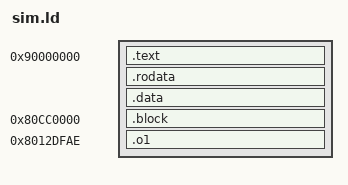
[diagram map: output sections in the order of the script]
ENTRY(__start)
SECTIONS
{
  . = 0x90000000; .text : { *(.text*) } .rodata : { *(.rodata*) } .data : { *(.data*) *(.bss*) *(COMMON) }
  __stack_top = 0x900fff00;
  .block 0x80cc0000 : { *(.block) }
  .o1 0x8012dfae : { *(.os_12dfae) }
}
